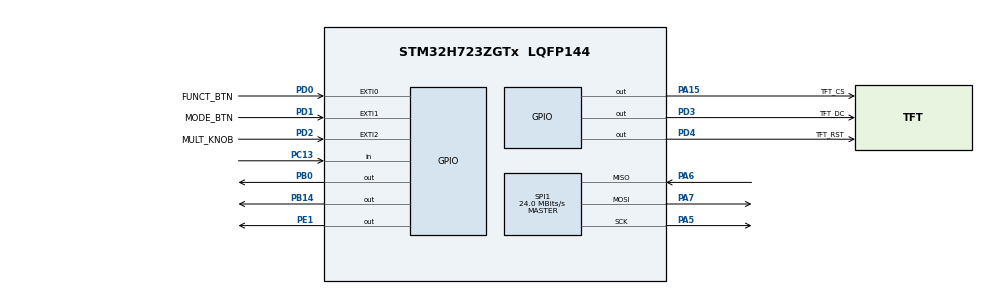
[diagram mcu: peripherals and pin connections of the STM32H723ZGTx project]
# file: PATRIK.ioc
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CORTEX_M7.default_mode_Activation=1
Mcu.Family=STM32H7
Mcu.Name=STM32H723ZGTx
Mcu.Package=LQFP144
NUCLEO-H723ZG.BUTTON=1
NUCLEO-H723ZG.LD1=true
NUCLEO-H723ZG.LD2=true
NUCLEO-H723ZG.LD3=true
NUCLEO-H723ZG.VCP=true
NVIC.EXTI0_IRQn=true\:0\:0\:false\:false\:true\:true\:true\:true
NVIC.EXTI15_10_IRQn=true\:0\:0\:false\:false\:true\:false\:true\:true
NVIC.EXTI1_IRQn=true\:0\:0\:false\:false\:true\:true\:true\:true
NVIC.EXTI2_IRQn=true\:0\:0\:false\:false\:true\:true\:true\:true
NVIC.PriorityGroup=NVIC_PRIORITYGROUP_4
PA13(JTMS/SWDIO).GPIO_Label=SWDIO
PA13(JTMS/SWDIO).Signal=DEBUG_JTMS-SWDIO
PA14(JTCK/SWCLK).GPIO_Label=SWCLK
PA14(JTCK/SWCLK).Signal=DEBUG_JTCK-SWCLK
PA15(JTDI).GPIO_Label=TFT_CS
PA15(JTDI).Signal=GPIO_Output
PA5.Mode=Full_Duplex_Master
PA5.Signal=SPI1_SCK
PA6.Mode=Full_Duplex_Master
PA6.Signal=SPI1_MISO
PA7.Mode=Full_Duplex_Master
PA7.Signal=SPI1_MOSI
PB0.Signal=GPIO_Output
PB14.Signal=GPIO_Output
PC13.Signal=GPIO_Input
PC14-OSC32_IN.Signal=RCC_OSC32_IN
PC15-OSC32_OUT.Signal=RCC_OSC32_OUT
PD0.GPIO_Label=FUNCT_BTN
PD0.GPIO_ModeDefaultEXTI=GPIO_MODE_IT_FALLING
PD0.Signal=GPXTI0
PD1.GPIO_Label=MODE_BTN
PD1.GPIO_ModeDefaultEXTI=GPIO_MODE_IT_FALLING
PD1.Signal=GPXTI1
PD2.GPIO_Label=MULT_KNOB
PD2.GPIO_ModeDefaultEXTI=GPIO_MODE_IT_FALLING
PD2.Signal=GPXTI2
PD3.GPIO_Label=TFT_DC
PD3.Signal=GPIO_Output
PD4.GPIO_Label=TFT_RST
PD4.Signal=GPIO_Output
PD8.Signal=USART3_TX
PD9.Signal=USART3_RX
PE1.Signal=GPIO_Output
ProjectManager.HeapSize=0x200
ProjectManager.StackSize=0x400
ProjectManager.TargetToolchain=STM32CubeIDE
RCC.ADCFreq_Value=608000000
RCC.APB1Freq_Value=48000000
RCC.APB2Freq_Value=48000000
RCC.APB3Freq_Value=48000000
RCC.APB4Freq_Value=48000000
RCC.CortexFreq_Value=192000000
RCC.D1PPRE=RCC_APB3_DIV2
RCC.D2PPRE1=RCC_APB1_DIV2
RCC.D2PPRE2=RCC_APB2_DIV2
RCC.D3PPRE=RCC_APB4_DIV2
RCC.DIVM1=4
RCC.DIVM2=1
RCC.DIVN1=12
RCC.DIVN2=19
RCC.DIVP1=1
RCC.DIVQ1=4
RCC.HCLKFreq_Value=96000000
RCC.HPRE=RCC_HCLK_DIV2
RCC.HSE_VALUE=8000000
RCC.PLL2FRACN=0
RCC.PLL3FRACN=0
RCC.PLLFRACN=0
RCC.SYSCLKFreq_VALUE=192000000
RCC.SYSCLKSource=RCC_SYSCLKSOURCE_PLLCLK
RCC.USBCLockSelection=RCC_USBCLKSOURCE_HSI48
RCC.USBFreq_Value=48000000
SPI1.BaudRatePrescaler=SPI_BAUDRATEPRESCALER_2
SPI1.CalculateBaudRate=24.0 MBits/s
SPI1.DataSize=SPI_DATASIZE_8BIT
SPI1.Direction=SPI_DIRECTION_2LINES
SPI1.Mode=SPI_MODE_MASTER
SPI1.VirtualType=VM_MASTER
VP_MEMORYMAP_VS_MEMORYMAP.Mode=CurAppReg
VP_NUCLEO-H723ZG_VS_BSP_COMMON.Mode=COMMON
board=NUCLEO-H723ZG

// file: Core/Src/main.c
/* USER CODE BEGIN Header */
/**
  ******************************************************************************
  * @file           : main.c
  * @brief          : Main program body
  ******************************************************************************
  * @attention
  *
  * Copyright (c) 2025 STMicroelectronics.
  * All rights reserved.
  *
  * This software is licensed under terms that can be found in the LICENSE file
  * in the root directory of this software component.
  * If no LICENSE file comes with this software, it is provided AS-IS.
  *
  ******************************************************************************
  */
/* USER CODE END Header */
#include "main.h"

COM_InitTypeDef BspCOMInit;

SPI_HandleTypeDef hspi1;

void SystemClock_Config(void);
static void MPU_Config(void);
static void MX_GPIO_Init(void);
static void MX_SPI1_Init(void);
/* USER CODE BEGIN PFP */
void app_main(void);
/* USER CODE END PFP */

int main(void)
{

  /* MPU Configuration--------------------------------------------------------*/
  MPU_Config();

  /* MCU Configuration--------------------------------------------------------*/

  /* Reset of all peripherals, Initializes the Flash interface and the Systick. */
  HAL_Init();

  /* Configure the system clock */
  SystemClock_Config();

  /* Initialize all configured peripherals */
  MX_GPIO_Init();
  MX_SPI1_Init();

  /* Initialize leds */
  BSP_LED_Init(LED_GREEN);
  BSP_LED_Init(LED_YELLOW);
  BSP_LED_Init(LED_RED);

  /* Initialize USER push-button, will be used to trigger an interrupt each time it's pressed.*/
  BSP_PB_Init(BUTTON_USER, BUTTON_MODE_EXTI);

  /* Initialize COM1 port (115200, 8 bits (7-bit data + 1 stop bit), no parity */
  BspCOMInit.BaudRate   = 115200;
  BspCOMInit.WordLength = COM_WORDLENGTH_8B;
  BspCOMInit.StopBits   = COM_STOPBITS_1;
  BspCOMInit.Parity     = COM_PARITY_NONE;
  BspCOMInit.HwFlowCtl  = COM_HWCONTROL_NONE;
  if (BSP_COM_Init(COM1, &BspCOMInit) != BSP_ERROR_NONE)
  {
    Error_Handler();
  }

  /* Infinite loop */
  /* USER CODE BEGIN WHILE */
  app_main();
  while (1)
  {

    /* USER CODE END WHILE */

  }
}

void SystemClock_Config(void)
{
  RCC_OscInitTypeDef RCC_OscInitStruct = {0};
  RCC_ClkInitTypeDef RCC_ClkInitStruct = {0};

  /** Supply configuration update enable
  */
  HAL_PWREx_ConfigSupply(PWR_LDO_SUPPLY);

  /** Configure the main internal regulator output voltage
  */
  __HAL_PWR_VOLTAGESCALING_CONFIG(PWR_REGULATOR_VOLTAGE_SCALE2);

  while(!__HAL_PWR_GET_FLAG(PWR_FLAG_VOSRDY)) {}

  /** Initializes the RCC Oscillators according to the specified parameters
  * in the RCC_OscInitTypeDef structure.
  */
  RCC_OscInitStruct.OscillatorType = RCC_OSCILLATORTYPE_HSI;
  RCC_OscInitStruct.HSIState = RCC_HSI_DIV1;
  RCC_OscInitStruct.HSICalibrationValue = 64;
  RCC_OscInitStruct.PLL.PLLState = RCC_PLL_ON;
  RCC_OscInitStruct.PLL.PLLSource = RCC_PLLSOURCE_HSI;
  RCC_OscInitStruct.PLL.PLLM = 4;
  RCC_OscInitStruct.PLL.PLLN = 12;
  RCC_OscInitStruct.PLL.PLLP = 1;
  RCC_OscInitStruct.PLL.PLLQ = 4;
  RCC_OscInitStruct.PLL.PLLR = 2;
  RCC_OscInitStruct.PLL.PLLRGE = RCC_PLL1VCIRANGE_3;
  RCC_OscInitStruct.PLL.PLLVCOSEL = RCC_PLL1VCOWIDE;
  RCC_OscInitStruct.PLL.PLLFRACN = 0;
  if (HAL_RCC_OscConfig(&RCC_OscInitStruct) != HAL_OK)
  {
    Error_Handler();
  }

  /** Initializes the CPU, AHB and APB buses clocks
  */
  RCC_ClkInitStruct.ClockType = RCC_CLOCKTYPE_HCLK|RCC_CLOCKTYPE_SYSCLK
                              |RCC_CLOCKTYPE_PCLK1|RCC_CLOCKTYPE_PCLK2
                              |RCC_CLOCKTYPE_D3PCLK1|RCC_CLOCKTYPE_D1PCLK1;
  RCC_ClkInitStruct.SYSCLKSource = RCC_SYSCLKSOURCE_PLLCLK;
  RCC_ClkInitStruct.SYSCLKDivider = RCC_SYSCLK_DIV1;
  RCC_ClkInitStruct.AHBCLKDivider = RCC_HCLK_DIV2;
  RCC_ClkInitStruct.APB3CLKDivider = RCC_APB3_DIV2;
  RCC_ClkInitStruct.APB1CLKDivider = RCC_APB1_DIV2;
  RCC_ClkInitStruct.APB2CLKDivider = RCC_APB2_DIV2;
  RCC_ClkInitStruct.APB4CLKDivider = RCC_APB4_DIV2;

  if (HAL_RCC_ClockConfig(&RCC_ClkInitStruct, FLASH_LATENCY_1) != HAL_OK)
  {
    Error_Handler();
  }
}

static void MX_SPI1_Init(void)
{

  /* SPI1 parameter configuration*/
  hspi1.Instance = SPI1;
  hspi1.Init.Mode = SPI_MODE_MASTER;
  hspi1.Init.Direction = SPI_DIRECTION_2LINES;
  hspi1.Init.DataSize = SPI_DATASIZE_8BIT;
  hspi1.Init.CLKPolarity = SPI_POLARITY_LOW;
  hspi1.Init.CLKPhase = SPI_PHASE_1EDGE;
  hspi1.Init.NSS = SPI_NSS_SOFT;
  hspi1.Init.BaudRatePrescaler = SPI_BAUDRATEPRESCALER_2;
  hspi1.Init.FirstBit = SPI_FIRSTBIT_MSB;
  hspi1.Init.TIMode = SPI_TIMODE_DISABLE;
  hspi1.Init.CRCCalculation = SPI_CRCCALCULATION_DISABLE;
  hspi1.Init.CRCPolynomial = 0x0;
  hspi1.Init.NSSPMode = SPI_NSS_PULSE_ENABLE;
  hspi1.Init.NSSPolarity = SPI_NSS_POLARITY_LOW;
  hspi1.Init.FifoThreshold = SPI_FIFO_THRESHOLD_01DATA;
  hspi1.Init.TxCRCInitializationPattern = SPI_CRC_INITIALIZATION_ALL_ZERO_PATTERN;
  hspi1.Init.RxCRCInitializationPattern = SPI_CRC_INITIALIZATION_ALL_ZERO_PATTERN;
  hspi1.Init.MasterSSIdleness = SPI_MASTER_SS_IDLENESS_00CYCLE;
  hspi1.Init.MasterInterDataIdleness = SPI_MASTER_INTERDATA_IDLENESS_00CYCLE;
  hspi1.Init.MasterReceiverAutoSusp = SPI_MASTER_RX_AUTOSUSP_DISABLE;
  hspi1.Init.MasterKeepIOState = SPI_MASTER_KEEP_IO_STATE_DISABLE;
  hspi1.Init.IOSwap = SPI_IO_SWAP_DISABLE;
  if (HAL_SPI_Init(&hspi1) != HAL_OK)
  {
    Error_Handler();
  }

}

static void MX_GPIO_Init(void)
{
  GPIO_InitTypeDef GPIO_InitStruct = {0};

  /* GPIO Ports Clock Enable */
  __HAL_RCC_GPIOC_CLK_ENABLE();
  __HAL_RCC_GPIOA_CLK_ENABLE();
  __HAL_RCC_GPIOD_CLK_ENABLE();

  /*Configure GPIO pin Output Level */
  HAL_GPIO_WritePin(TFT_CS_GPIO_Port, TFT_CS_Pin, GPIO_PIN_RESET);

  /*Configure GPIO pin Output Level */
  HAL_GPIO_WritePin(GPIOD, TFT_DC_Pin|TFT_RST_Pin, GPIO_PIN_RESET);

  /*Configure GPIO pin : TFT_CS_Pin */
  GPIO_InitStruct.Pin = TFT_CS_Pin;
  GPIO_InitStruct.Mode = GPIO_MODE_OUTPUT_PP;
  GPIO_InitStruct.Pull = GPIO_NOPULL;
  GPIO_InitStruct.Speed = GPIO_SPEED_FREQ_LOW;
  HAL_GPIO_Init(TFT_CS_GPIO_Port, &GPIO_InitStruct);

  /*Configure GPIO pins : FUNCT_BTN_Pin MODE_BTN_Pin MULT_KNOB_Pin */
  GPIO_InitStruct.Pin = FUNCT_BTN_Pin|MODE_BTN_Pin|MULT_KNOB_Pin;
  GPIO_InitStruct.Mode = GPIO_MODE_IT_FALLING;
  GPIO_InitStruct.Pull = GPIO_NOPULL;
  HAL_GPIO_Init(GPIOD, &GPIO_InitStruct);

  /*Configure GPIO pins : TFT_DC_Pin TFT_RST_Pin */
  GPIO_InitStruct.Pin = TFT_DC_Pin|TFT_RST_Pin;
  GPIO_InitStruct.Mode = GPIO_MODE_OUTPUT_PP;
  GPIO_InitStruct.Pull = GPIO_NOPULL;
  GPIO_InitStruct.Speed = GPIO_SPEED_FREQ_LOW;
  HAL_GPIO_Init(GPIOD, &GPIO_InitStruct);

  /* EXTI interrupt init*/
  HAL_NVIC_SetPriority(FUNCT_BTN_EXTI_IRQn, 0, 0);
  HAL_NVIC_EnableIRQ(FUNCT_BTN_EXTI_IRQn);

  HAL_NVIC_SetPriority(MODE_BTN_EXTI_IRQn, 0, 0);
  HAL_NVIC_EnableIRQ(MODE_BTN_EXTI_IRQn);

  HAL_NVIC_SetPriority(MULT_KNOB_EXTI_IRQn, 0, 0);
  HAL_NVIC_EnableIRQ(MULT_KNOB_EXTI_IRQn);

}

/* USER CODE BEGIN 4 */
void HAL_GPIO_EXTI_Callback(uint16_t GPIO_Pin) {
	switch (GPIO_Pin) {
	case FUNCT_BTN_Pin:
		funct_toggle();
		break;
	case MODE_BTN_Pin:
		mode_toggle();
		break;
	default:
		__NOP();
		break;
	}
}
/* USER CODE END 4 */

 /* MPU Configuration */

void MPU_Config(void)
{
  MPU_Region_InitTypeDef MPU_InitStruct = {0};

  /* Disables the MPU */
  HAL_MPU_Disable();

  /** Initializes and configures the Region and the memory to be protected
  */
  MPU_InitStruct.Enable = MPU_REGION_ENABLE;
  MPU_InitStruct.Number = MPU_REGION_NUMBER0;
  MPU_InitStruct.BaseAddress = 0x0;
  MPU_InitStruct.Size = MPU_REGION_SIZE_4GB;
  MPU_InitStruct.SubRegionDisable = 0x87;
  MPU_InitStruct.TypeExtField = MPU_TEX_LEVEL0;
  MPU_InitStruct.AccessPermission = MPU_REGION_NO_ACCESS;
  MPU_InitStruct.DisableExec = MPU_INSTRUCTION_ACCESS_DISABLE;
  MPU_InitStruct.IsShareable = MPU_ACCESS_SHAREABLE;
  MPU_InitStruct.IsCacheable = MPU_ACCESS_NOT_CACHEABLE;
  MPU_InitStruct.IsBufferable = MPU_ACCESS_NOT_BUFFERABLE;

  HAL_MPU_ConfigRegion(&MPU_InitStruct);
  /* Enables the MPU */
  HAL_MPU_Enable(MPU_PRIVILEGED_DEFAULT);

}

void Error_Handler(void)
{
  __disable_irq();
  while (1)
  {
  }
}
